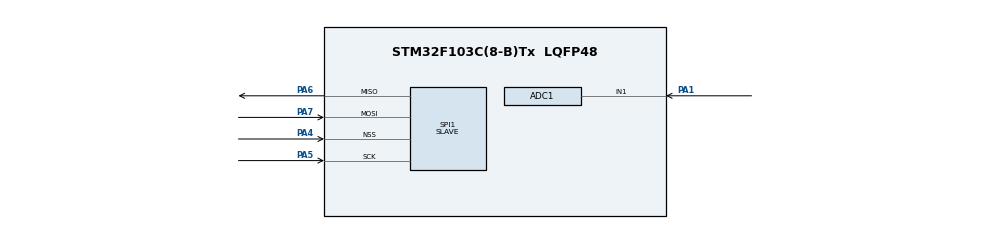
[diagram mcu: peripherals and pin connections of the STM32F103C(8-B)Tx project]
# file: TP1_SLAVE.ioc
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ADC1.Channel-0\#ChannelRegularConversion=ADC_CHANNEL_1
ADC1.NbrOfConversionFlag=1
ADC1.Rank-0\#ChannelRegularConversion=1
ADC1.SamplingTime-0\#ChannelRegularConversion=ADC_SAMPLETIME_1CYCLE_5
ADC1.master=1
Mcu.Family=STM32F1
Mcu.Name=STM32F103C(8-B)Tx
Mcu.Package=LQFP48
NVIC.PriorityGroup=NVIC_PRIORITYGROUP_4
PA1.Signal=ADCx_IN1
PA4.Mode=NSS_Signal_Hard_Input
PA4.Signal=SPI1_NSS
PA5.Mode=Full_Duplex_Slave
PA5.Signal=SPI1_SCK
PA6.Mode=Full_Duplex_Slave
PA6.Signal=SPI1_MISO
PA7.Mode=Full_Duplex_Slave
PA7.Signal=SPI1_MOSI
ProjectManager.HeapSize=0x200
ProjectManager.StackSize=0x400
ProjectManager.TargetToolchain=STM32CubeIDE
RCC.APB1Freq_Value=8000000
RCC.APB2Freq_Value=8000000
SH.ADCx_IN1.0=ADC1_IN1,IN1
SPI1.Direction=SPI_DIRECTION_2LINES
SPI1.Mode=SPI_MODE_SLAVE
SPI1.VirtualNSS=VM_NSSHARD
SPI1.VirtualType=VM_SLAVE
board=custom

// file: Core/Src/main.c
/* USER CODE BEGIN Header */
/**
  ******************************************************************************
  * @file           : main.c
  * @brief          : Main program body
  ******************************************************************************
  * @attention
  *
  * Copyright (c) 2026 STMicroelectronics.
  * All rights reserved.
  *
  * This software is licensed under terms that can be found in the LICENSE file
  * in the root directory of this software component.
  * If no LICENSE file comes with this software, it is provided AS-IS.
  *
  ******************************************************************************
  */
/* USER CODE END Header */
#include "main.h"

ADC_HandleTypeDef hadc1;
SPI_HandleTypeDef hspi1;

/* USER CODE BEGIN PV */
uint8_t txData = 0;
uint8_t rxData = 0;
uint16_t adcValue = 0;
/* USER CODE END PV */

void SystemClock_Config(void);
static void MX_GPIO_Init(void);
static void MX_ADC1_Init(void);
static void MX_SPI1_Init(void);

int main(void)
{

  /* MCU Configuration--------------------------------------------------------*/

  HAL_Init();

  SystemClock_Config();

  MX_GPIO_Init();
  MX_ADC1_Init();
  MX_SPI1_Init();

  /* USER CODE BEGIN 2 */
  HAL_ADC_Start(&hadc1);
  /* USER CODE END 2 */

  /* Infinite loop */
  /* USER CODE BEGIN WHILE */
  while (1)
  {
    HAL_ADC_PollForConversion(&hadc1, HAL_MAX_DELAY);
    adcValue = HAL_ADC_GetValue(&hadc1);

    txData = adcValue >> 4;

    HAL_SPI_TransmitReceive(&hspi1, &txData, &rxData, 1, HAL_MAX_DELAY);

    HAL_ADC_Start(&hadc1);
    /* USER CODE END WHILE */

  }
}

void SystemClock_Config(void)
{
  RCC_OscInitTypeDef RCC_OscInitStruct = {0};
  RCC_ClkInitTypeDef RCC_ClkInitStruct = {0};
  RCC_PeriphCLKInitTypeDef PeriphClkInit = {0};

  RCC_OscInitStruct.OscillatorType = RCC_OSCILLATORTYPE_HSI;
  RCC_OscInitStruct.HSIState = RCC_HSI_ON;
  RCC_OscInitStruct.HSICalibrationValue = RCC_HSICALIBRATION_DEFAULT;
  RCC_OscInitStruct.PLL.PLLState = RCC_PLL_NONE;
  if (HAL_RCC_OscConfig(&RCC_OscInitStruct) != HAL_OK)
  {
    Error_Handler();
  }

  RCC_ClkInitStruct.ClockType = RCC_CLOCKTYPE_HCLK | RCC_CLOCKTYPE_SYSCLK
                              | RCC_CLOCKTYPE_PCLK1 | RCC_CLOCKTYPE_PCLK2;
  RCC_ClkInitStruct.SYSCLKSource = RCC_SYSCLKSOURCE_HSI;
  RCC_ClkInitStruct.AHBCLKDivider = RCC_SYSCLK_DIV1;
  RCC_ClkInitStruct.APB1CLKDivider = RCC_HCLK_DIV1;
  RCC_ClkInitStruct.APB2CLKDivider = RCC_HCLK_DIV1;

  if (HAL_RCC_ClockConfig(&RCC_ClkInitStruct, FLASH_LATENCY_0) != HAL_OK)
  {
    Error_Handler();
  }

  PeriphClkInit.PeriphClockSelection = RCC_PERIPHCLK_ADC;
  PeriphClkInit.AdcClockSelection = RCC_ADCPCLK2_DIV2;
  if (HAL_RCCEx_PeriphCLKConfig(&PeriphClkInit) != HAL_OK)
  {
    Error_Handler();
  }
}

static void MX_ADC1_Init(void)
{
  ADC_ChannelConfTypeDef sConfig = {0};

  hadc1.Instance = ADC1;
  hadc1.Init.ScanConvMode = ADC_SCAN_DISABLE;
  hadc1.Init.ContinuousConvMode = DISABLE;
  hadc1.Init.DiscontinuousConvMode = DISABLE;
  hadc1.Init.ExternalTrigConv = ADC_SOFTWARE_START;
  hadc1.Init.DataAlign = ADC_DATAALIGN_RIGHT;
  hadc1.Init.NbrOfConversion = 1;
  if (HAL_ADC_Init(&hadc1) != HAL_OK)
  {
    Error_Handler();
  }

  sConfig.Channel = ADC_CHANNEL_1;
  sConfig.Rank = ADC_REGULAR_RANK_1;
  sConfig.SamplingTime = ADC_SAMPLETIME_1CYCLE_5;
  if (HAL_ADC_ConfigChannel(&hadc1, &sConfig) != HAL_OK)
  {
    Error_Handler();
  }
}

static void MX_SPI1_Init(void)
{
  hspi1.Instance = SPI1;
  hspi1.Init.Mode = SPI_MODE_SLAVE;
  hspi1.Init.Direction = SPI_DIRECTION_2LINES;
  hspi1.Init.DataSize = SPI_DATASIZE_8BIT;
  hspi1.Init.CLKPolarity = SPI_POLARITY_LOW;
  hspi1.Init.CLKPhase = SPI_PHASE_1EDGE;
  hspi1.Init.NSS = SPI_NSS_HARD_INPUT;
  hspi1.Init.FirstBit = SPI_FIRSTBIT_MSB;
  hspi1.Init.TIMode = SPI_TIMODE_DISABLE;
  hspi1.Init.CRCCalculation = SPI_CRCCALCULATION_DISABLE;
  hspi1.Init.CRCPolynomial = 10;
  if (HAL_SPI_Init(&hspi1) != HAL_OK)
  {
    Error_Handler();
  }
}

static void MX_GPIO_Init(void)
{
  __HAL_RCC_GPIOA_CLK_ENABLE();
}

void Error_Handler(void)
{
  __disable_irq();
  while (1)
  {
  }
}
